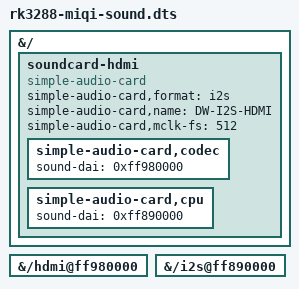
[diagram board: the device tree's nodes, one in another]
/dts-v1/;
/plugin/;

&{/} {
   soundcard-hdmi {
     compatible = "simple-audio-card";
     simple-audio-card,format = "i2s";
     simple-audio-card,name = "DW-I2S-HDMI";
     simple-audio-card,mclk-fs = <512>;
     simple-audio-card,codec {
       // &hdmi
       sound-dai = <0xff980000>;
     };
     simple-audio-card,cpu {
       // &i2s
       sound-dai = <0xff890000>;
     };
   };
};

// &hdmi
&{/hdmi@ff980000} {
  #address-cells = <1>;
  #size-cells = <0>;
  #sound-dai-cells = <0>;
};

// &i2s
&{/i2s@ff890000} {
  #sound-dai-cells = <0>;
  status = "okay";
};

// Need this?
// &hdmi {
//   pinctrl-names = "default";
//   pinctrl-0 = <&hdmi_cec_c0>;
// };
